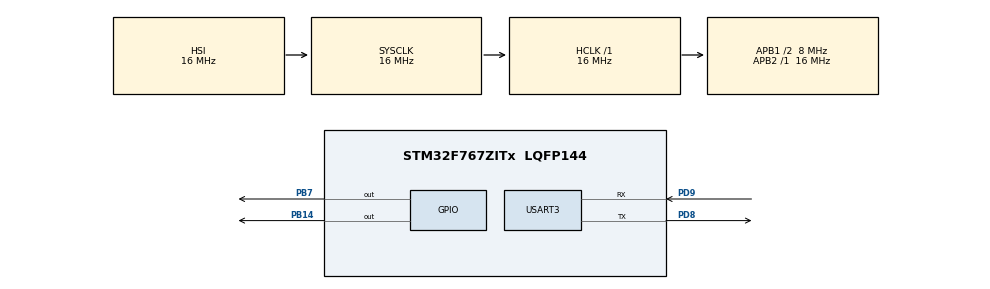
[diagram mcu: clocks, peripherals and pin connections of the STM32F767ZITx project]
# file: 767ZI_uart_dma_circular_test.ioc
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Dma.Request0=USART3_RX
Dma.USART3_RX.0.Direction=DMA_PERIPH_TO_MEMORY
Dma.USART3_RX.0.FIFOMode=DMA_FIFOMODE_DISABLE
Dma.USART3_RX.0.Instance=DMA1_Stream1
Dma.USART3_RX.0.MemDataAlignment=DMA_MDATAALIGN_BYTE
Dma.USART3_RX.0.MemInc=DMA_MINC_ENABLE
Dma.USART3_RX.0.Mode=DMA_CIRCULAR
Dma.USART3_RX.0.PeriphDataAlignment=DMA_PDATAALIGN_BYTE
Dma.USART3_RX.0.PeriphInc=DMA_PINC_DISABLE
Dma.USART3_RX.0.Priority=DMA_PRIORITY_MEDIUM
FREERTOS.Queues01=myQueue01,128,uint8_t,NULL,Dynamic,NULL,NULL
FREERTOS.Tasks01=defaultTask,0,128,StartDefaultTask,Default,NULL,Dynamic,NULL,NULL;myTaskUartRecei,0,128,StartTaskUartReceive,Default,NULL,Dynamic,NULL,NULL;myTaskLed,-2,128,StartTaskLed,Default,NULL,Dynamic,NULL,NULL
Mcu.Family=STM32F7
Mcu.Name=STM32F767ZITx
Mcu.Package=LQFP144
NVIC.DMA1_Stream1_IRQn=true\:5\:0\:false\:false\:true\:true\:false
NVIC.PriorityGroup=NVIC_PRIORITYGROUP_4
NVIC.TIM1_UP_TIM10_IRQn=true\:0\:0\:false\:false\:true\:false\:false
NVIC.TimeBase=TIM1_UP_TIM10_IRQn
NVIC.TimeBaseIP=TIM1
PB14.Signal=GPIO_Output
PB7.Signal=GPIO_Output
PD8.Mode=Asynchronous
PD8.Signal=USART3_TX
PD9.Mode=Asynchronous
PD9.Signal=USART3_RX
ProjectManager.HeapSize=0x200
ProjectManager.StackSize=0x400
ProjectManager.TargetToolchain=SW4STM32
RCC.48MHZClocksFreq_Value=24000000
RCC.AHBFreq_Value=16000000
RCC.APB1CLKDivider=RCC_HCLK_DIV2
RCC.APB1Freq_Value=8000000
RCC.APB1TimFreq_Value=16000000
RCC.APB2Freq_Value=16000000
RCC.APB2TimFreq_Value=16000000
RCC.CortexFreq_Value=16000000
RCC.HCLKFreq_Value=16000000
RCC.HSE_VALUE=16000000
RCC.HSI_VALUE=16000000
RCC.LSE_VALUE=32768
RCC.PLLMUL=RCC_PLL_MUL9
RCC.PRESCALERUSB=RCC_USBCLKSOURCE_PLL_DIV1_5
RCC.SYSCLKFreq_VALUE=16000000
RCC.SYSCLKSourceVirtual=RCC_SYSCLKSOURCE_PLLCLK
RCC.USBFreq_Value=96000000
RCC.VCOOutputFreq_Value=192000000
USART3.VirtualMode-Asynchronous=VM_ASYNC
USART3.WordLength=WORDLENGTH_8B
VP_FREERTOS_VS_ENABLE.Mode=Enabled
VP_SYS_VS_tim1.Mode=TIM1
board=NUCLEO-F767ZI

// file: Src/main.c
/**
  ******************************************************************************
  * File Name          : main.c
  * Description        : Main program body
  ******************************************************************************
  * This notice applies to any and all portions of this file
  * that are not between comment pairs USER CODE BEGIN and
  * USER CODE END. Other portions of this file, whether
  * inserted by the user or by software development tools
  * are owned by their respective copyright owners.
  *
  * Copyright (c) 2017 STMicroelectronics International N.V.
  * All rights reserved.
  *
  * Redistribution and use in source and binary forms, with or without
  * modification, are permitted, provided that the following conditions are met:
  *
  * 1. Redistribution of source code must retain the above copyright notice,
  *    this list of conditions and the following disclaimer.
  * 2. Redistributions in binary form must reproduce the above copyright notice,
  *    this list of conditions and the following disclaimer in the documentation
  *    and/or other materials provided with the distribution.
  * 3. Neither the name of STMicroelectronics nor the names of other
  *    contributors to this software may be used to endorse or promote products
  *    derived from this software without specific written permission.
  * 4. This software, including modifications and/or derivative works of this
  *    software, must execute solely and exclusively on microcontroller or
  *    microprocessor devices manufactured by or for STMicroelectronics.
  * 5. Redistribution and use of this software other than as permitted under
  *    this license is void and will automatically terminate your rights under
  *    this license.
  *
  * THIS SOFTWARE IS PROVIDED BY STMICROELECTRONICS AND CONTRIBUTORS "AS IS"
  * AND ANY EXPRESS, IMPLIED OR STATUTORY WARRANTIES, INCLUDING, BUT NOT
  * LIMITED TO, THE IMPLIED WARRANTIES OF MERCHANTABILITY, FITNESS FOR A
  * PARTICULAR PURPOSE AND NON-INFRINGEMENT OF THIRD PARTY INTELLECTUAL PROPERTY
  * RIGHTS ARE DISCLAIMED TO THE FULLEST EXTENT PERMITTED BY LAW. IN NO EVENT
  * SHALL STMICROELECTRONICS OR CONTRIBUTORS BE LIABLE FOR ANY DIRECT, INDIRECT,
  * INCIDENTAL, SPECIAL, EXEMPLARY, OR CONSEQUENTIAL DAMAGES (INCLUDING, BUT NOT
  * LIMITED TO, PROCUREMENT OF SUBSTITUTE GOODS OR SERVICES; LOSS OF USE, DATA,
  * OR PROFITS; OR BUSINESS INTERRUPTION) HOWEVER CAUSED AND ON ANY THEORY OF
  * LIABILITY, WHETHER IN CONTRACT, STRICT LIABILITY, OR TORT (INCLUDING
  * NEGLIGENCE OR OTHERWISE) ARISING IN ANY WAY OUT OF THE USE OF THIS SOFTWARE,
  * EVEN IF ADVISED OF THE POSSIBILITY OF SUCH DAMAGE.
  *
  ******************************************************************************
  */

#include "main.h"
#include "stm32f7xx_hal.h"
#include "cmsis_os.h"

UART_HandleTypeDef huart3;
DMA_HandleTypeDef hdma_usart3_rx;

osThreadId defaultTaskHandle;
osThreadId myTaskUartReceiHandle;
osThreadId myTaskLedHandle;
osMessageQId myQueue01Handle;

/* USER CODE BEGIN PV */
/* Private variables ---------------------------------------------------------*/
unsigned char i,j,k,RxData,tab[60];
#define CIRC_BUF_SZ       16  /* must be power of two */
static uint8_t rx_dma_circ_buf[CIRC_BUF_SZ];
/* USER CODE END PV */

void SystemClock_Config(void);
static void MX_GPIO_Init(void);
static void MX_DMA_Init(void);
static void MX_USART3_UART_Init(void);
void StartDefaultTask(void const * argument);
void StartTaskUartReceive(void const * argument);
void StartTaskLed(void const * argument);

/* USER CODE BEGIN PFP */
/* Private function prototypes -----------------------------------------------*/

/* USER CODE END PFP */

int main(void)
{

  /* MCU Configuration----------------------------------------------------------*/

  /* Reset of all peripherals, Initializes the Flash interface and the Systick. */
  HAL_Init();

  /* Configure the system clock */
  SystemClock_Config();

  /* Initialize all configured peripherals */
  MX_GPIO_Init();
  MX_DMA_Init();
  MX_USART3_UART_Init();

  /* USER CODE BEGIN 2 */
  HAL_UART_Receive_DMA(&huart3, rx_dma_circ_buf, 16);

  /* USER CODE END 2 */

  /* Create the thread(s) */
  /* definition and creation of defaultTask */
  osThreadDef(defaultTask, StartDefaultTask, osPriorityNormal, 0, 128);
  defaultTaskHandle = osThreadCreate(osThread(defaultTask), NULL);

  /* definition and creation of myTaskUartRecei */
  osThreadDef(myTaskUartRecei, StartTaskUartReceive, osPriorityNormal, 0, 128);
  myTaskUartReceiHandle = osThreadCreate(osThread(myTaskUartRecei), NULL);

  /* definition and creation of myTaskLed */
  osThreadDef(myTaskLed, StartTaskLed, osPriorityLow, 0, 128);
  myTaskLedHandle = osThreadCreate(osThread(myTaskLed), NULL);

  /* Create the queue(s) */
  /* definition and creation of myQueue01 */
  osMessageQDef(myQueue01, 128, uint8_t);
  myQueue01Handle = osMessageCreate(osMessageQ(myQueue01), NULL);

  /* USER CODE BEGIN RTOS_QUEUES */
  /* add queues, ... */
  /* Create a UART TX queue capable of containing 10 message (data frames) */
  /* USER CODE END RTOS_QUEUES */

  /* Start scheduler */
  osKernelStart();

  /* We should never get here as control is now taken by the scheduler */

  /* Infinite loop */
  while (1)
  {

  }

}

/** System Clock Configuration
*/
void SystemClock_Config(void)
{

  RCC_OscInitTypeDef RCC_OscInitStruct;
  RCC_ClkInitTypeDef RCC_ClkInitStruct;
  RCC_PeriphCLKInitTypeDef PeriphClkInitStruct;

    /**Configure the main internal regulator output voltage
    */
  __HAL_RCC_PWR_CLK_ENABLE();

  __HAL_PWR_VOLTAGESCALING_CONFIG(PWR_REGULATOR_VOLTAGE_SCALE3);

    /**Initializes the CPU, AHB and APB busses clocks
    */
  RCC_OscInitStruct.OscillatorType = RCC_OSCILLATORTYPE_HSI;
  RCC_OscInitStruct.HSIState = RCC_HSI_ON;
  RCC_OscInitStruct.HSICalibrationValue = 16;
  RCC_OscInitStruct.PLL.PLLState = RCC_PLL_NONE;
  if (HAL_RCC_OscConfig(&RCC_OscInitStruct) != HAL_OK)
  {
    _Error_Handler(__FILE__, __LINE__);
  }

    /**Initializes the CPU, AHB and APB busses clocks
    */
  RCC_ClkInitStruct.ClockType = RCC_CLOCKTYPE_HCLK|RCC_CLOCKTYPE_SYSCLK
                              |RCC_CLOCKTYPE_PCLK1|RCC_CLOCKTYPE_PCLK2;
  RCC_ClkInitStruct.SYSCLKSource = RCC_SYSCLKSOURCE_HSI;
  RCC_ClkInitStruct.AHBCLKDivider = RCC_SYSCLK_DIV1;
  RCC_ClkInitStruct.APB1CLKDivider = RCC_HCLK_DIV2;
  RCC_ClkInitStruct.APB2CLKDivider = RCC_HCLK_DIV1;

  if (HAL_RCC_ClockConfig(&RCC_ClkInitStruct, FLASH_LATENCY_0) != HAL_OK)
  {
    _Error_Handler(__FILE__, __LINE__);
  }

  PeriphClkInitStruct.PeriphClockSelection = RCC_PERIPHCLK_USART3;
  PeriphClkInitStruct.Usart3ClockSelection = RCC_USART3CLKSOURCE_PCLK1;
  if (HAL_RCCEx_PeriphCLKConfig(&PeriphClkInitStruct) != HAL_OK)
  {
    _Error_Handler(__FILE__, __LINE__);
  }

    /**Configure the Systick interrupt time
    */
  HAL_SYSTICK_Config(HAL_RCC_GetHCLKFreq()/1000);

    /**Configure the Systick
    */
  HAL_SYSTICK_CLKSourceConfig(SYSTICK_CLKSOURCE_HCLK);

  /* SysTick_IRQn interrupt configuration */
  HAL_NVIC_SetPriority(SysTick_IRQn, 15, 0);
}

/* USART3 init function */
static void MX_USART3_UART_Init(void)
{

  huart3.Instance = USART3;
  huart3.Init.BaudRate = 115200;
  huart3.Init.WordLength = UART_WORDLENGTH_8B;
  huart3.Init.StopBits = UART_STOPBITS_1;
  huart3.Init.Parity = UART_PARITY_NONE;
  huart3.Init.Mode = UART_MODE_TX_RX;
  huart3.Init.HwFlowCtl = UART_HWCONTROL_NONE;
  huart3.Init.OverSampling = UART_OVERSAMPLING_16;
  huart3.Init.OneBitSampling = UART_ONE_BIT_SAMPLE_DISABLE;
  huart3.AdvancedInit.AdvFeatureInit = UART_ADVFEATURE_NO_INIT;
  if (HAL_UART_Init(&huart3) != HAL_OK)
  {
    _Error_Handler(__FILE__, __LINE__);
  }

}

static void MX_DMA_Init(void)
{
  /* DMA controller clock enable */
  __HAL_RCC_DMA1_CLK_ENABLE();

  /* DMA interrupt init */
  /* DMA1_Stream1_IRQn interrupt configuration */
  HAL_NVIC_SetPriority(DMA1_Stream1_IRQn, 5, 0);
  HAL_NVIC_EnableIRQ(DMA1_Stream1_IRQn);

}

/** Configure pins as
        * Analog
        * Input
        * Output
        * EVENT_OUT
        * EXTI
*/
static void MX_GPIO_Init(void)
{

  GPIO_InitTypeDef GPIO_InitStruct;

  /* GPIO Ports Clock Enable */
  __HAL_RCC_GPIOB_CLK_ENABLE();
  __HAL_RCC_GPIOD_CLK_ENABLE();

  /*Configure GPIO pin Output Level */
  HAL_GPIO_WritePin(GPIOB, GPIO_PIN_14|GPIO_PIN_7, GPIO_PIN_RESET);

  /*Configure GPIO pins : PB14 PB7 */
  GPIO_InitStruct.Pin = GPIO_PIN_14|GPIO_PIN_7;
  GPIO_InitStruct.Mode = GPIO_MODE_OUTPUT_PP;
  GPIO_InitStruct.Pull = GPIO_NOPULL;
  GPIO_InitStruct.Speed = GPIO_SPEED_FREQ_LOW;
  HAL_GPIO_Init(GPIOB, &GPIO_InitStruct);

}

/* StartDefaultTask function */
void StartDefaultTask(void const * argument)
{

  /* USER CODE BEGIN 5 */

  /* Infinite loop */
  for(;;)
  {
	HAL_GPIO_TogglePin(GPIOB,GPIO_PIN_14);
    osDelay(500);
  }
  /* USER CODE END 5 */
}

/* StartTaskUartReceive function */
void StartTaskUartReceive(void const * argument)
{
  /* USER CODE BEGIN StartTaskUartReceive */
	unsigned char i;

  /* Infinite loop */
  for(;;)
  {
	  j=sprintf(tab,"BUFFER: \n"); if(HAL_UART_Transmit(&huart3, (uint8_t *)&tab,j,5000)!= HAL_OK) Error_Handler();
	  for(i=0;i<CIRC_BUF_SZ;++i)
	  {
		  j=sprintf(tab,"%02X \n",rx_dma_circ_buf[i]); if(HAL_UART_Transmit(&huart3, (uint8_t *)&tab,j,50)!= HAL_OK) Error_Handler();
	  };

	  HAL_GPIO_TogglePin(GPIOB,GPIO_PIN_7);
	  HAL_Delay(100);
  }
  /* USER CODE END StartTaskUartReceive */
}

/* StartTaskLed function */
void StartTaskLed(void const * argument)
{
  for(;;)
  {
    osDelay(1);
  }
}

void HAL_TIM_PeriodElapsedCallback(TIM_HandleTypeDef *htim)
{
  if (htim->Instance == TIM1) {
    HAL_IncTick();
  }
}

void _Error_Handler(char * file, int line)
{
  while(1)
  {
  }
}

/************************ (C) COPYRIGHT STMicroelectronics *****END OF FILE****/
